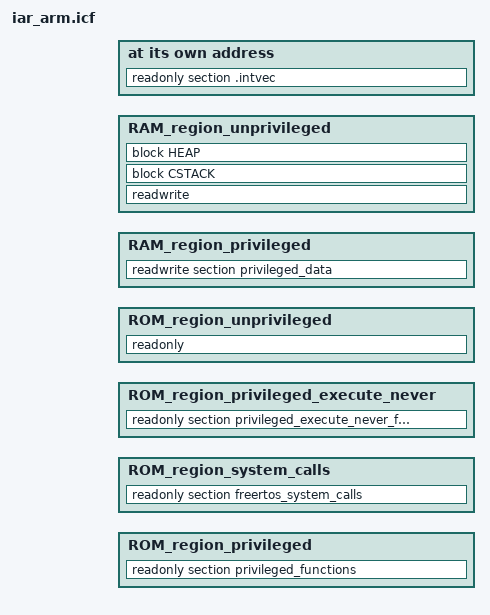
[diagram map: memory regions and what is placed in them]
/*
 * Copyright (c) 2009-2024 Arm Limited. All rights reserved.
 *
 * SPDX-License-Identifier: Apache-2.0
 *
 * Licensed under the Apache License, Version 2.0 (the License); you may
 * not use this file except in compliance with the License.
 * You may obtain a copy of the License at
 *
 * www.apache.org/licenses/LICENSE-2.0
 *
 * Unless required by applicable law or agreed to in writing, software
 * distributed under the License is distributed on an AS IS BASIS, WITHOUT
 * WARRANTIES OR CONDITIONS OF ANY KIND, either express or implied.
 * See the License for the specific language governing permissions and
 * limitations under the License.
 */  

define symbol BL2_HEADER_SIZE                          = 0x400;
define symbol FLASH_NS_PARTITION_SIZE                  = 0x340000;
define symbol FLASH_S_PARTITION_SIZE                   = 0x40000;
define symbol ROM_START                                = 0x28000000;
define symbol NS_ROM_START                             = (ROM_START + ((((0) + (FLASH_S_PARTITION_SIZE)) + BL2_HEADER_SIZE)));
define symbol ISRAM0_BASE_ADDRESS                      = 0x21000000;
define symbol ISRAM1_OFFSET                            = 0x00200000;
define symbol ISRAM1_SIZE                              = 0x00200000;
define symbol _PRIVILEGED_FUNCTIONS_REGION_SIZE_       = 0x00010000;
define symbol _PRIVILEGED_SRAM_REGION_SIZE_            = 0x00100000;

define symbol _privileged_functions_start_           = (NS_ROM_START);
define symbol _privileged_functions_end_             = ((_privileged_functions_start_ + _PRIVILEGED_FUNCTIONS_REGION_SIZE_) - 0x1);
define symbol _system_calls_start_                   = (_privileged_functions_end_ + 0x1);
define symbol _system_calls_end_                     = ((_system_calls_start_ + 0x1000) - 0x1);
define symbol _privileged_execute_never_start_       = (_system_calls_end_ + 0x1);
define symbol _privileged_execute_never_end_         = (_privileged_execute_never_start_ + 0x20 - 0x1);
define symbol _unprivileged_functions_start_         = (_privileged_execute_never_end_ + 0x1);
define symbol _unprivileged_functions_end_           = ((NS_ROM_START + FLASH_NS_PARTITION_SIZE) - 0x1);

define symbol _SRAM_segment_start_                   = (ISRAM0_BASE_ADDRESS + ISRAM1_OFFSET);
define symbol _SRAM_segment_end_                     = ((_SRAM_segment_start_ + ISRAM1_SIZE) - 0x1);
define symbol _privileged_sram_start_                = (_SRAM_segment_start_);
define symbol _privileged_sram_end_                  = ((_privileged_sram_start_ + _PRIVILEGED_SRAM_REGION_SIZE_) - 0x1);
define symbol _uprivileged_sram_start_               = (_privileged_sram_end_ + 0x1);
define symbol _unprivileged_sram_end_                = (_SRAM_segment_end_);

define block CSTACK with alignment = 8, size = 0x00001000 { };
define block HEAP   with alignment = 8, size = 0x00080000 { };

/* Memory regions. */
define region ROM_region_privileged                   = mem:[from _privileged_functions_start_ to _privileged_functions_end_];
define region ROM_region_system_calls                 = mem:[from _system_calls_start_ to _system_calls_end_];
define region ROM_region_privileged_execute_never     = mem:[from _privileged_execute_never_start_ to _privileged_execute_never_end_];
define region ROM_region_unprivileged                 = mem:[from _unprivileged_functions_start_ to _unprivileged_functions_end_];

define region RAM_region_privileged                   = mem:[from _privileged_sram_start_ to _privileged_sram_end_];
define region RAM_region_unprivileged                 = mem:[from _uprivileged_sram_start_ to _unprivileged_sram_end_];

/* Initialization. */
initialize by copy { readwrite };
do not initialize { section .noinit };

/* Exported symbols. */
define exported symbol __FLASH_segment_start__              = NS_ROM_START;
define exported symbol __FLASH_segment_end__                = NS_ROM_START + FLASH_NS_PARTITION_SIZE;
define exported symbol __SRAM_segment_start__               = _SRAM_segment_start_;
define exported symbol __SRAM_segment_end__                 = _SRAM_segment_end_;

define exported symbol __privileged_functions_start__       = _privileged_functions_start_;
define exported symbol __privileged_functions_end__         = _privileged_functions_end_;
define exported symbol __privileged_execute_never_start__   = _privileged_execute_never_start_;
define exported symbol __privileged_execute_never_end__     = _privileged_execute_never_end_;
define exported symbol __unprivileged_flash_start__         = _unprivileged_functions_start_;
define exported symbol __unprivileged_flash_end__           = _unprivileged_functions_end_;
define exported symbol __privileged_sram_start__            = _privileged_sram_start_;
define exported symbol __privileged_sram_end__              = _privileged_sram_end_;

define exported symbol __syscalls_flash_start__             = _system_calls_start_;
define exported symbol __syscalls_flash_end__               = _system_calls_end_;

/* Placements. */
place at address mem:NS_ROM_START                 { readonly section .intvec };

place in ROM_region_privileged                    { readonly section privileged_functions };
place in ROM_region_system_calls                  { readonly section freertos_system_calls };
place in ROM_region_privileged_execute_never      { readonly section privileged_execute_never_functions };
place in ROM_region_unprivileged                  { readonly };

place in RAM_region_privileged                    { readwrite section privileged_data };
place in RAM_region_unprivileged                  { readwrite, block CSTACK, block HEAP };
